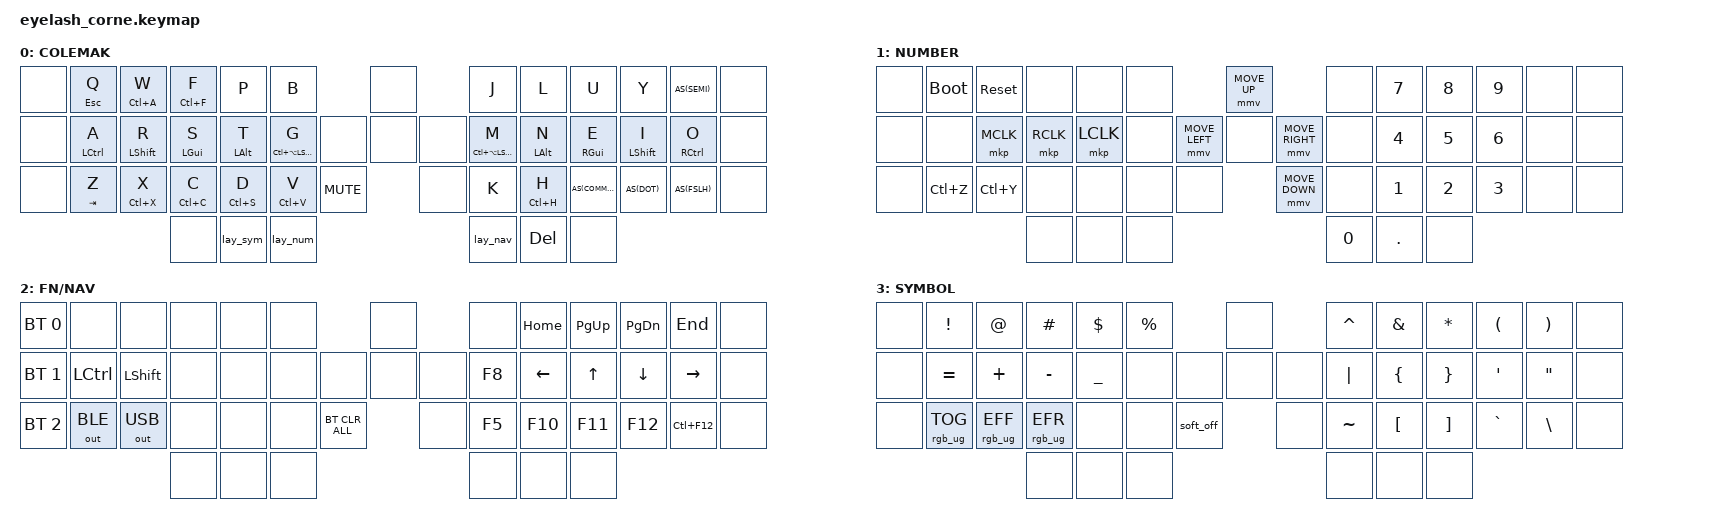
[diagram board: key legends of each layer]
#define ZMK_POINTING_DEFAULT_MOVE_VAL 1200  // 600
#define ZMK_POINTING_DEFAULT_SCRL_VAL 25   // 10
#define AS(keycode) &as LS(keycode) keycode

#include <input/processors.dtsi>
#include <zephyr/dt-bindings/input/input-event-codes.h>
#include <behaviors.dtsi>
#include <dt-bindings/zmk/bt.h>
#include <dt-bindings/zmk/keys.h>
#include <dt-bindings/zmk/outputs.h>
#include <dt-bindings/zmk/pointing.h>
#include <dt-bindings/zmk/rgb.h>
#include <dt-bindings/zmk/ext_power.h>

&mmv_input_listener { input-processors = <&zip_xy_scaler 2 1>; };
&msc_input_listener { input-processors = <&zip_scroll_scaler 2 1>; };

&msc {
    acceleration-exponent = <1>;
    time-to-max-speed-ms = <100>;
    delay-ms = <0>;
};

&mmv {
    time-to-max-speed-ms = <500>;
    acceleration-exponent = <1>;
    trigger-period-ms = <16>;
};

/ {
    combos {
        compatible = "zmk,combos";
        combo_tab {
            key-positions = <17 23>;
            bindings = <&kp TAB>;
        };

        combo_shifttab {
            key-positions = <16 24>;
            bindings = <&kp LS(TAB)>;
        };
        combo_capslock {
            key-positions = <15 25>;
            bindings = <&kp CAPSLOCK>;
        };

        combo_capsword {
            key-positions = <14 26>;
            bindings = <&caps_word>;
        };

        combo_power {
            key-positions = <42 47>;
            bindings = <&ext_power EP_TOG>;
        };
    };

    macros {
        lay_num: lay_num {
            compatible = "zmk,behavior-macro";
            #binding-cells = <0>;
            bindings =
                <&macro_press>,
                <&ltp 1 SPACE>,
                <&macro_tap>,
                <&rgb_ug RGB_COLOR_HSB(240,100,50)>,
                <&macro_pause_for_release>,
                <&macro_release>,
                <&ltp 1 SPACE>,
                <&macro_tap>,
                <&rgb_ug RGB_COLOR_HSB(230,90,50)>;
        };

        lay_nav: lay_nav {
            compatible = "zmk,behavior-macro";
            #binding-cells = <0>;
            bindings =
                <&macro_press>,
                <&ltp 2 ENTER>,
                <&macro_tap>,
                <&rgb_ug RGB_COLOR_HSB(125,100,50)>,
                <&macro_pause_for_release>,
                <&macro_release>,
                <&ltp 2 ENTER>,
                <&macro_tap>,
                <&rgb_ug RGB_COLOR_HSB(230,90,50)>;
        };

        lay_sym: lay_sym {
            compatible = "zmk,behavior-macro";
            #binding-cells = <0>;
            bindings =
                <&macro_press>,
                <&ltp 3 BSPC>,
                <&macro_tap>,
                <&rgb_ug RGB_COLOR_HSB(195,100,50)>,
                <&macro_pause_for_release>,
                <&macro_release>,
                <&ltp 3 BSPC>,
                <&macro_tap>,
                <&rgb_ug RGB_COLOR_HSB(230,90,50)>;
        };
    };

    behaviors {
        ht: hold_tap {
            compatible = "zmk,behavior-hold-tap";
            #binding-cells = <2>;
            flavor = "tap-preferred";
            tapping-term-ms = <200>;
            bindings = <&kp>, <&kp>;
            display-name = "Hold Tap";
        };

        as: auto_shift {
            compatible = "zmk,behavior-hold-tap";
            #binding-cells = <2>;
            tapping_term_ms = <135>;
            quick_tap_ms = <0>;
            flavor = "tap-preferred";
            bindings = <&kp>, <&kp>;
        };

        hml: home_row_mod_left {
            compatible = "zmk,behavior-hold-tap";
            #binding-cells = <2>;
            flavor = "balanced";
            require-prior-idle-ms = <150>;
            tapping-term-ms = <280>;
            quick-tap-ms = <175>;
            bindings = <&kp>, <&kp>;
            hold-trigger-key-positions = <7 8 9 10 11 12 22 23 24 25 26 27 36 37 38 39 40 41>; // List of keys on the right side of the keyboard
            hold-trigger-on-release;
        };

        hmr: home_row_mod_right {
            compatible = "zmk,behavior-hold-tap";
            #binding-cells = <2>;
            flavor = "balanced";
            require-prior-idle-ms = <150>;
            tapping-term-ms = <280>;
            quick-tap-ms = <175>;
            bindings = <&kp>, <&kp>;
            hold-trigger-key-positions = <0 1 2 3 4 5 13 14 15 16 17 18 28 29 30 31 32 33>; // List of keys on the left side of the keyboard
            hold-trigger-on-release;
        };

        ltp: layertap {
            compatible = "zmk,behavior-hold-tap";
            #binding-cells = <2>;
            flavor = "tap-preferred";
            tapping-term-ms = <200>;
            quick-tap-ms = <175>;
            bindings = <&mo>, <&kp>;
            display-name = "Layer-Tap";
        };
    };

    keymap {
        compatible = "zmk,keymap";

        default_layer {
            display-name = "COLEMAK";
            bindings = <
&none  &ht ESC Q     &ht LC(A) W    &ht LC(F) F  &kp P        &kp B                                         &none          &kp J                   &kp L        &kp U       &kp Y         AS(SEMI)     &none
&none  &hml LCTRL A  &hml LSHIFT R  &hml LGUI S  &hml LALT T  &hml LC(LA(LSHIFT)) G                  &none  &none &none    &hmr LC(LA(LSHIFT)) M   &hmr LALT N  &hmr RGUI E &hmr LSHIFT I &hmr RCTRL O &none
&none  &ht TAB Z     &ht LC(X) X    &ht LC(C) C  &ht LC(S) D  &ht LC(V) V              &kp C_MUTE           &none          &kp K                   &ht LC(H) H  AS(COMMA)   AS(DOT)       AS(FSLH)     &none
                                    &none        &lay_sym     &lay_num                                                     &lay_nav                &kp DEL      &none
            >;

            sensor-bindings = <&inc_dec_kp C_VOLUME_UP C_VOLUME_DOWN>;
        };

        lower_layer {
            display-name = "NUMBER";
            bindings = <
&none  &bootloader  &sys_reset  &none      &none      &none                           &mmv MOVE_UP                     &none   &kp N7      &kp N8  &kp N9  &none  &none
&none  &none        &mkp MCLK   &mkp RCLK  &mkp LCLK  &none           &mmv MOVE_LEFT  &none           &mmv MOVE_RIGHT  &none   &kp N4      &kp N5  &kp N6  &none  &none
&none  &kp LC(Z)    &kp LC(Y)   &none      &none      &none   &none                   &mmv MOVE_DOWN                   &none   &kp N1      &kp N2  &kp N3  &none  &none
                                &none      &none      &none                                                            &kp N0  &kp PERIOD  &none
            >;
        };

        raise_layer {
            display-name = "FN/NAV";
            bindings = < 
&bt BT_SEL 0  &none         &none          &none   &none    &none                           &none        &none   &kp HOME  &kp PG_UP  &kp PG_DN  &kp END      &none
&bt BT_SEL 1  &kp LCTRL     &kp LSHIFT     &none   &none    &none                    &none  &none &none  &kp F8  &kp LEFT  &kp UP     &kp DOWN   &kp RIGHT    &none
&bt BT_SEL 2  &out OUT_BLE  &out OUT_USB   &none   &none    &none   &bt BT_CLR_ALL          &none        &kp F5  &kp F10   &kp F11    &kp F12    &kp LC(F12)  &none
                                           &none   &none    &none                                        &none   &none     &none
            >;
        };

        symbol_layer {
            display-name = "SYMBOL";
            bindings = <
&none  &kp EXCL         &kp AT           &kp HASH         &kp DLLR    &kp PRCNT                    &none        &kp CARET  &kp AMPS  &kp ASTRK  &kp LPAR          &kp RPAR           &none
&none  &kp EQUAL        &kp PLUS         &kp MINUS        &kp UNDER   &none                 &none  &none &none  &kp PIPE   &kp LBRC  &kp RBRC   &kp SINGLE_QUOTE  &kp DOUBLE_QUOTES  &none
&none  &rgb_ug RGB_TOG  &rgb_ug RGB_EFF  &rgb_ug RGB_EFR  &none       &none      &soft_off         &none        &kp TILDE  &kp LBKT  &kp RBKT   &kp GRAVE         &kp BSLH           &none
                                         &none            &none       &none                                     &none      &none     &none
            >;
        };
    };
};
